# CH32X315 register map
Vendor: WCH Ltd.; File version: 1.1
Registers are 32-bit, read-write, reset 0x0 unless marked. A register's access mark holds for its fields unless they carry their own. Offsets are from the block's base; [hi:lo] are bit positions; {n}, {i} and the like mark numbered series.

## AFIO — Alternate function I/O
Base 0x40010000
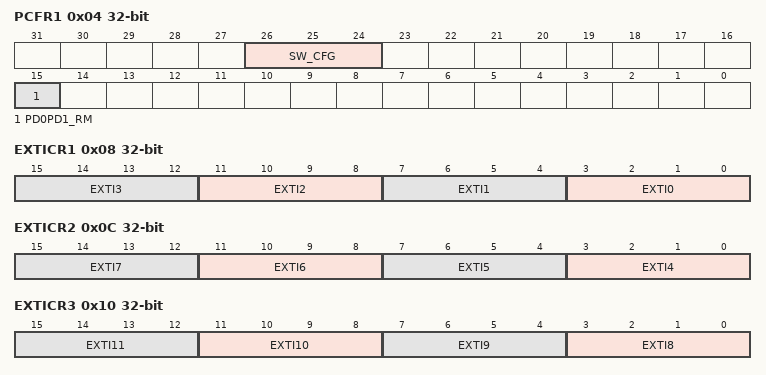
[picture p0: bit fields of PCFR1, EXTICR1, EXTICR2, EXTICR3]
0x04 PCFR1 — AF remap and debug I/O configuration register (AFIO_PCFR1)
  [26:24] SW_CFG — Serial wire JTAG configuration
  [15] PD0PD1_RM — PD0PD1 remapping
0x08 EXTICR1 — External interrupt configuration register 1
  [4n+3:4n] EXTI{n} (n=0..3) — External interrupt {n} input pin configuration
0x0C EXTICR2 — External interrupt configuration register 2
  [4n-13:4n-16] EXTI{n} (n=4..7) — External interrupt {n} input pin configuration
0x10 EXTICR3 — External interrupt configuration register 3
  [4n-29:4n-32] EXTI{n} (n=8..11) — External interrupt {n} input pin configuration
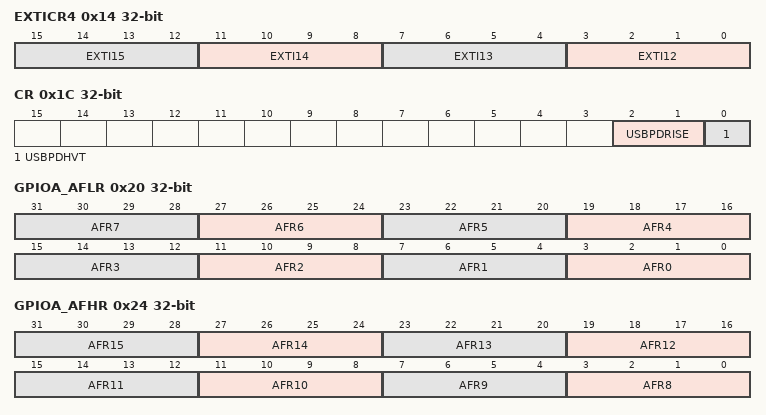
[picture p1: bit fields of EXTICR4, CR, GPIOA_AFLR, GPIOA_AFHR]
0x14 EXTICR4 — External interrupt configuration register 4
  [4n-45:4n-48] EXTI{n} (n=12..15) — External interrupt {n} input pin configuration
0x1C CR — control register
  [2:1] USBPDRISE — The Tr adjustment of the USBPD LV waveform is user-adjustment
  [0] USBPDHVT — CC pin intput channel threshold adjustment
0x20 GPIOA_AFLR — PA port multiplexing function register
  [4n+3:4n] AFR{n} (n=0..7) — selection of multiplexing function for pin {n} of PA port
0x24 GPIOA_AFHR — PA port multiplexing function register
  [4n-29:4n-32] AFR{n} (n=8..15) — selection of multiplexing function for pin {n} of PA port
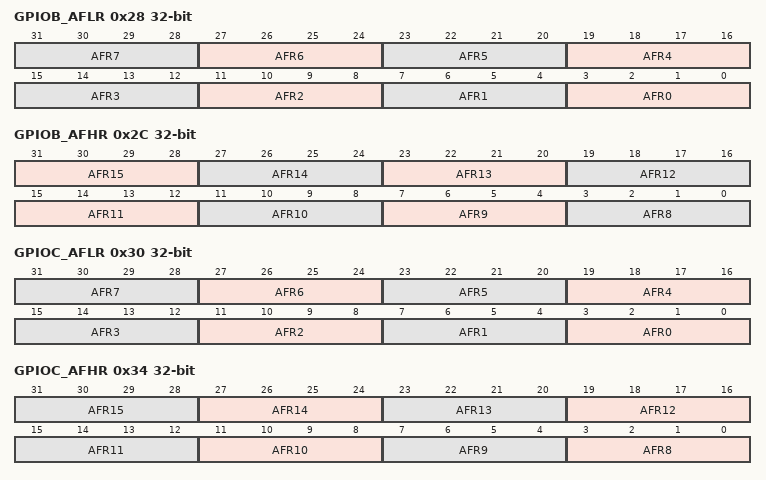
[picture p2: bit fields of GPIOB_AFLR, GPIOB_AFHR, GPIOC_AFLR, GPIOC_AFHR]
0x28 GPIOB_AFLR — PB port multiplexing function register
  [4n+3:4n] AFR{n} (n=0..7) — selection of multiplexing function for pin {n} of PB port
0x2C GPIOB_AFHR — PB port multiplexing function register
  [4n-29:4n-32] AFR{n} (n=9..15) — selection of multiplexing function for pin {n} of PB port
  [3:0] AFR8 — selection of multiplexing function for pin 8 of PA port
0x30 GPIOC_AFLR — PC port multiplexing function register
  [4n+3:4n] AFR{n} (n=0..7) — selection of multiplexing function for pin {n} of PC port
0x34 GPIOC_AFHR — PC port multiplexing function register
  [4n-29:4n-32] AFR{n} (n=8..15) — selection of multiplexing function for pin {n} of PC port
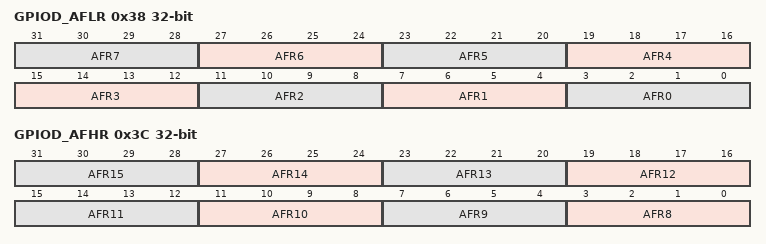
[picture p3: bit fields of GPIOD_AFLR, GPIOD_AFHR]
0x38 GPIOD_AFLR — PD port multiplexing function register
  [4n+3:4n] AFR{n} (n=4..7) — selection of multiplexing function for pin {n} of PD port
  [15:12] AFR3 — selection of multiplexing function for pin 3 of PA port
  [11:8] AFR2 — selection of multiplexing function for pin 2 of PD port
  [7:4] AFR1 — selection of multiplexing function for pin 1 of PD port
  [3:0] AFR0 — selection of multiplexing function for pin 0 of PD port
0x3C GPIOD_AFHR — PD port multiplexing function register
  [4n-29:4n-32] AFR{n} (n=8..15) — selection of multiplexing function for pin {n} of PD port

## USART1 — Universal synchronous asynchronous receiver transmitter
Base 0x40013800
Same registers: USART2 0x40004400, USART3 0x40004800, UART4 0x40004C00
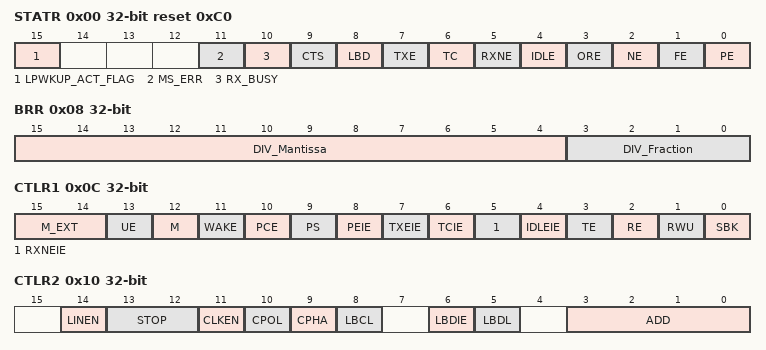
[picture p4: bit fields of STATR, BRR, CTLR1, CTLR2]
0x00 STATR access per field reset 0xC0 — Status register
  [15] LPWKUP_ACT_FLAG rw — Low power wake-up start indication bit
  [11] MS_ERR ro — MARK or SPACE check error flag
  [10] RX_BUSY ro — receive status indication bit
  [9] CTS rw — CTS flag
  [8] LBD rw — LIN break detection flag
  [7] TXE ro — Transmit data register empty
  [6] TC rw — Transmission complete
  [5] RXNE rw — Read data register not empty
  [4] IDLE ro — IDLE line detected
  [3] ORE ro — Overrun error
  [2] NE ro — Noise error flag
  [1] FE ro — Framing error
  [0] PE ro — Parity error
0x04 DATAR — Data register
  [8:0] DR — Data value
0x08 BRR — Baud rate register
  [15:4] DIV_Mantissa — mantissa of USARTDIV
  [3:0] DIV_Fraction — fraction of USARTDIV
0x0C CTLR1 — Control register 1
  [15:14] M_EXT — data length extension bit
  [13] UE — USART enable
  [12] M — Word length
  [11] WAKE — Wakeup method
  [10] PCE — Parity control enable
  [9] PS — Parity selection
  [8] PEIE — PE interrupt enable
  [7] TXEIE — TXE interrupt enable
  [6] TCIE — Transmission complete interrupt enable
  [5] RXNEIE — RXNE interrupt enable
  [4] IDLEIE — IDLE interrupt enable
  [3] TE — Transmitter enable
  [2] RE — Receiver enable
  [1] RWU — Receiver wakeup
  [0] SBK — Send break
0x10 CTLR2 — Control register 2
  [14] LINEN — LIN mode enable
  [13:12] STOP — STOP bits
  [11] CLKEN — Clock enable
  [10] CPOL — Clock polarity
  [9] CPHA — Clock phase
  [8] LBCL — Last bit clock pulse
  [6] LBDIE — LIN break detection interrupt enable
  [5] LBDL — lin break detection length
  [3:0] ADD — Address of the USART node
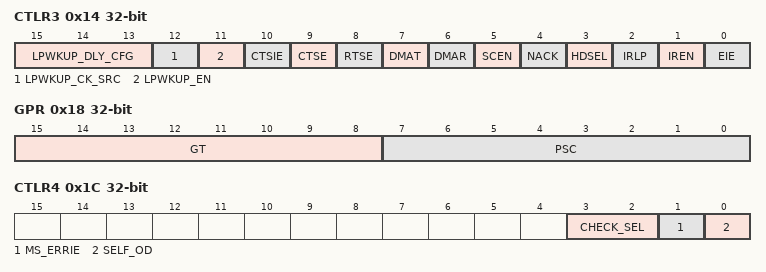
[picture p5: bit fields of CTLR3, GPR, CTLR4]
0x14 CTLR3 — Control register 3
  [15:13] LPWKUP_DLY_CFG — CTS interrupt enable
  [12] LPWKUP_CK_SRC — Low power wake-up clock source selection
  [11] LPWKUP_EN — Low power wake-up enablement
  [10] CTSIE — CTS interrupt enable
  [9] CTSE — CTS enable
  [8] RTSE — RTS enable
  [7] DMAT — DMA enable transmitter
  [6] DMAR — DMA enable receiver
  [5] SCEN — Smartcard mode enable
  [4] NACK — Smartcard NACK enable
  [3] HDSEL — Half-duplex selection
  [2] IRLP — IrDA low-power
  [1] IREN — IrDA mode enable
  [0] EIE — Error interrupt enable
0x18 GPR — Guard time and prescaler register
  [15:8] GT — Guard time value
  [7:0] PSC — Prescaler value
0x1C CTLR4 — Control register 4
  [3:2] CHECK_SEL — check function selection bit
  [1] MS_ERRIE — SPACE or mark check error enable bit
  [0] SELF_OD — open-drain output enable bit
